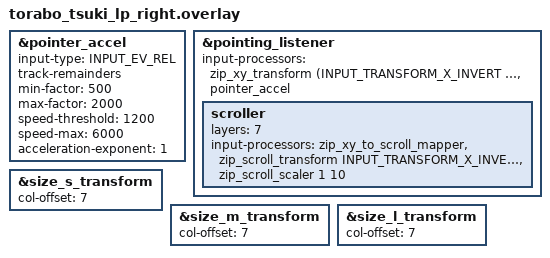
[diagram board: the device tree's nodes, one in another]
#define TORABO_TSUKI_LP_RIGHT 1

#include "torabo_tsuki_lp.dtsi"
#include <input/processors.dtsi>
#include <dt-bindings/zmk/input_transform.h>
#include <behaviors/input_gestures_accel.dtsi>
#include <zephyr/dt-bindings/input/input-event-codes.h>

&pointer_accel {
    input-type = <INPUT_EV_REL>;
    track-remainders;

    min-factor = <500>;
    max-factor = <2000>;
    speed-threshold = <1200>;
    speed-max = <6000>;
    acceleration-exponent = <1>;
};

&pointing_listener {
    input-processors = <
        &zip_xy_transform
            (INPUT_TRANSFORM_X_INVERT | INPUT_TRANSFORM_Y_INVERT)
        &pointer_accel>;
    scroller {
        layers = <7>;

        input-processors =
            <&zip_xy_to_scroll_mapper>,
            <&zip_scroll_transform INPUT_TRANSFORM_X_INVERT>,
            <&zip_scroll_scaler 1 10>;
    };
};

&size_s_transform {
    col-offset = <7>;
};

&size_m_transform {
    col-offset = <7>;
};

&size_l_transform {
    col-offset = <7>;
};
